# MB9BF40xN register map
File version: 1.7
Registers are 8-bit, read-write, reset 0x0 unless marked. A register's access mark holds for its fields unless they carry their own. Offsets are from the block's base; [hi:lo] are bit positions; {n}, {i} and the like mark numbered series; 'fields as' and 'values as' point back to an identical list.

## QPRC0 — Quadrature Position/Revolution Counter 0
Base 0x40026000
Same registers: QPRC1 0x40026040
0x00 QPCR 16-bit — QPRC Position Count Register
0x04 QRCR 16-bit — QPRC Revolution Count Register
0x08 QPCCR 16-bit — QPRC Position Counter Compare Register
0x0C QPRCR 16-bit — QPRC Position and Revolution Counter Compare Register
0x10 QMPR 16-bit reset 0xFFFF — QPRC Maximum Position Register
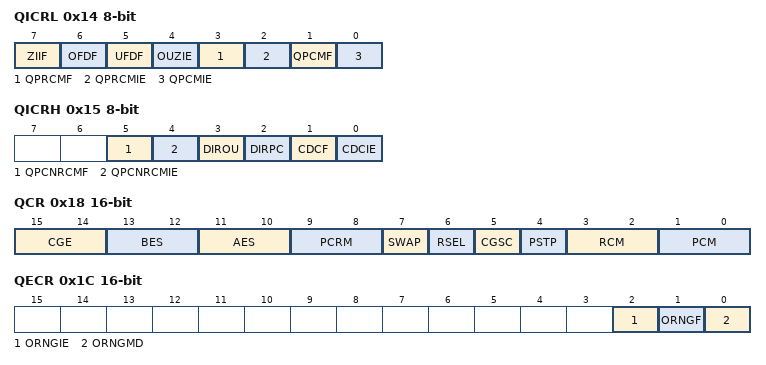
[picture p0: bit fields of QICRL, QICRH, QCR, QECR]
0x14 QICRL — Low-Order Bytes of QPRC Interrupt Control Register
  [7] ZIIF — Zero index interrupt request flag bit
  [6] OFDF — Overflow interrupt request flag bit
  [5] UFDF — Underflow interrupt request flag bit
  [4] OUZIE — "Overflow, underflow, or zero index interrupt enable bit"
  [3] QPRCMF — PC and RC match interrupt request flag bit
  [2] QPRCMIE — PC and RC match interrupt enable bit
  [1] QPCMF — PC match interrupt request flag bit
  [0] QPCMIE — PC match interrupt enable bit
0x15 QICRH — High-Order Bytes of QPRC Interrupt Control Register
  [5] QPCNRCMF — PC match and RC match interrupt request flag bit
  [4] QPCNRCMIE — PC match and RC match interrupt enable bit
  [3] DIROU ro — Last position counter flow direction bit
  [2] DIRPC ro — Last position counter direction bit
  [1] CDCF — Count inversion interrupt request flag bit
  [0] CDCIE — Count inversion interrupt enable bit
0x18 QCR 16-bit — QPRC Control Register
  [15:14] CGE — Detection edge selection bits
  [13:12] BES — BIN detection edge selection bits
  [11:10] AES — AIN detection edge selection bits
  [9:8] PCRM — Position counter reset mask bits
  [7] SWAP — Swap bit
  [6] RSEL — Register function selection bit
  [5] CGSC — Count clear or gate selection bit
  [4] PSTP — Position counter stop bit
  [3:2] RCM — Revolution counter mode bits
  [1:0] PCM — Position counter mode bits
0x1C QECR 16-bit — QPRC Extension Control Register
  [2] ORNGIE — Outrange interrupt enable bit
  [1] ORNGF — Outrange interrupt request flag bit
  [0] ORNGMD — Outrange mode selection bit

## WC — Watch Counter
Base 0x4003A000
0x00 WCRD ro — Watch Counter Read Register
  [5:0] CTR — counter value
0x01 WCRL — Watch Counter Reload Register
  [5:0] RLC — reload value
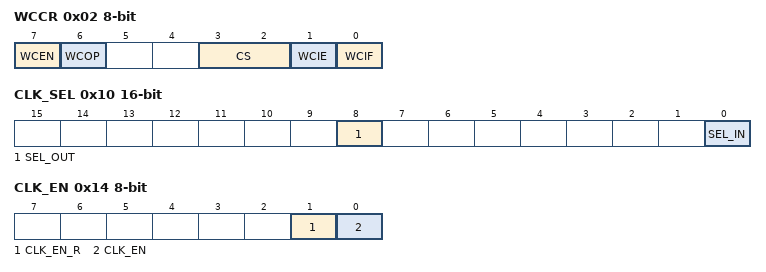
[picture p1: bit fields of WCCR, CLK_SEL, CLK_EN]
0x02 WCCR — Watch Counter Control Register
  [7] WCEN — Watch counter operation enable bit
  [6] WCOP ro — Watch counter operating state flag
  [3:2] CS — Count clock select bits
  [1] WCIE — Interrupt request enable bit
  [0] WCIF — Interrupt request flag bit
0x10 CLK_SEL 16-bit — Clock Selection Register
  [8] SEL_OUT — Output clock selection bit
  [0] SEL_IN — Input clock selection bit
0x14 CLK_EN — Division Clock Enable Register
  [1] CLK_EN_R — Division clock enable read bit
  [0] CLK_EN — Division clock enable bit

## EXTI — External Interrupt and NMI Control
Base 0x40030000
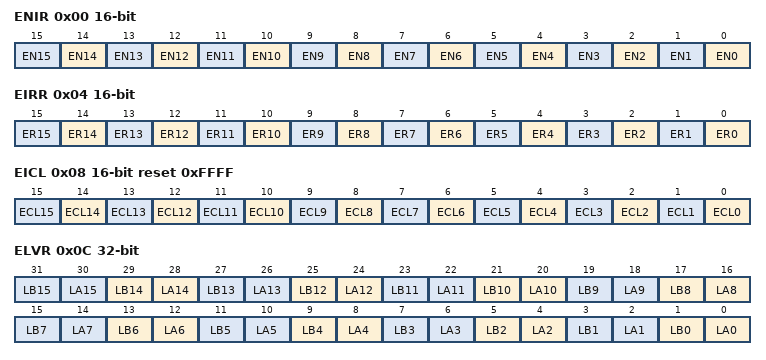
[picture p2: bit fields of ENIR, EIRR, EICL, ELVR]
0x00 ENIR 16-bit — Enable Interrupt Request Register
  [n] EN{n} (n=0..15) — Bit{n} of ENIR
0x04 EIRR 16-bit ro reset not defined — External Interrupt Request Register
  [n] ER{n} (n=0..15) — Bit{n} of EIRR
0x08 EICL 16-bit reset 0xFFFF — External Interrupt Clear Register
  [n] ECL{n} (n=0..15) — Bit{n} of EICL
0x0C ELVR 32-bit — External Interrupt Level Register
  [2n+1] LB{n} (n=0..15) — Bit{2n+1} of ELVR
  [2n] LA{n} (n=0..15) — Bit{2n} of ELVR
0x14 NMIRR ro — Non Maskable Interrupt Request Register
  [0] NR — NMI interrupt request detection bit
0x18 NMICL reset 0x1 — Non Maskable Interrupt Clear Register
  [0] NCL — NMI interrupt cause clear bit

## LVD — Low-voltage Detection
Base 0x40035000
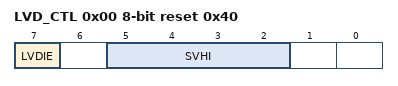
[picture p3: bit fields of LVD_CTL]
0x00 LVD_CTL reset 0x40 — Low-voltage Detection Voltage Control Register
  [7] LVDIE — Low-voltage detection interrupt enable bit
  [5:2] SVHI — Low-voltage detection interrupt voltage setting bits
0x04 LVD_STR ro — Low-voltage Detection Interrupt Register
  [7] LVDIR — Low-voltage detection interrupt bit
0x08 LVD_CLR reset 0x80 — Low-voltage Detection Interrupt Clear Register
  [7] LVDCL — Low-voltage detection interrupt clear bit
0x0C LVD_RLR 32-bit reset 0x1 — Low-voltage Detection Voltage Protection Register
  [31:0] LVDLCK — Low-voltage Detection Voltage Control Register protection bits
0x10 LVD_STR2 ro reset 0x40 — Low-voltage Detection Circuit Status Register
  [7] LVDIRDY — Low-voltage detection interrupt status flag

## CRC — CRC Registers
Base 0x40039000
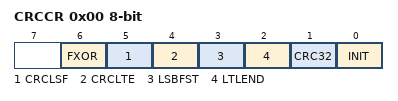
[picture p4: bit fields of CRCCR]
0x00 CRCCR — CRC Control Register
  [6] FXOR — Initialization bit
  [5] CRCLSF — Final XOR control bit
  [4] CRCLTE — CRC result bit-order setting bit
  [3] LSBFST — CRC result byte-order setting bit
  [2] LTLEND — Bit-order setting bit
  [1] CRC32 — Byte-order setting bit
  [0] INIT — CRC mode selection bit
0x04 CRCINIT 32-bit reset 0xFFFFFFFF — Initial Value Register
  [31:0] D — Initial value
0x08 CRCIN 32-bit — Input Data Register
  [31:0] D — Input data
0x0C CRCR 32-bit ro reset 0xFFFFFFFF — CRC Register
  [31:0] D — CRC Data

## EXBUS — External Bus Interface
Base 0x4003F000
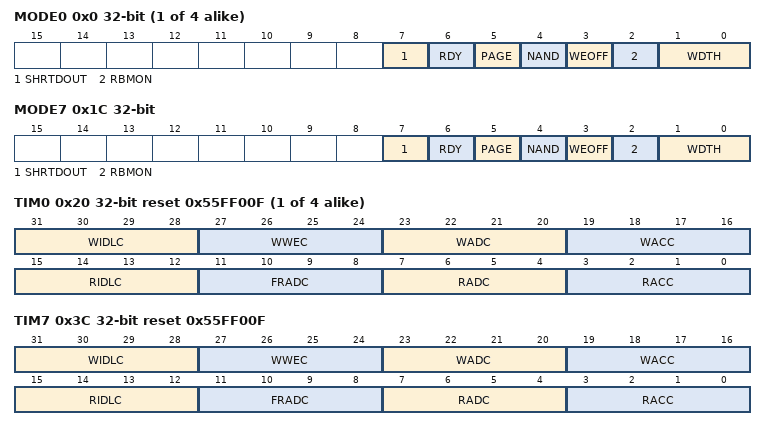
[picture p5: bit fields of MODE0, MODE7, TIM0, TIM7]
{0x0+4i} MODE{i} 32-bit (i=0..3) — Mode Register {i}
  [7] SHRTDOUT — select to which idle cycle the write data output is extended
  [6] RDY — control the external RDY function
  [5] PAGE — NOR Flash memory page access mode
  [4] NAND — NAND Flash memory mode
  [3] WEOFF — disable the write enable signal (MWEX) operation
  [2] RBMON — Read Byte Mask ON
  [1:0] WDTH — specify Data Width
0x1C MODE7 32-bit — Mode Register 7
  fields as MODE0
{0x20+4i} TIM{i} 32-bit reset 0x55FF00F (i=0..3) — Timing Register {i}
  [31:28] WIDLC — Write Idle Cycle
  [27:24] WWEC — Write Enable Cycle
  [23:20] WADC — Write Address Setup cycle
  [19:16] WACC — Write Access Cycle
  [15:12] RIDLC — Read Idle Cycle
  [11:8] FRADC — First Read Address Cycle
  [7:4] RADC — Read Address Setup cycle
  [3:0] RACC — Read Access Cycle
0x3C TIM7 32-bit reset 0x55FF00F — Timing Register 7
  fields as TIM0
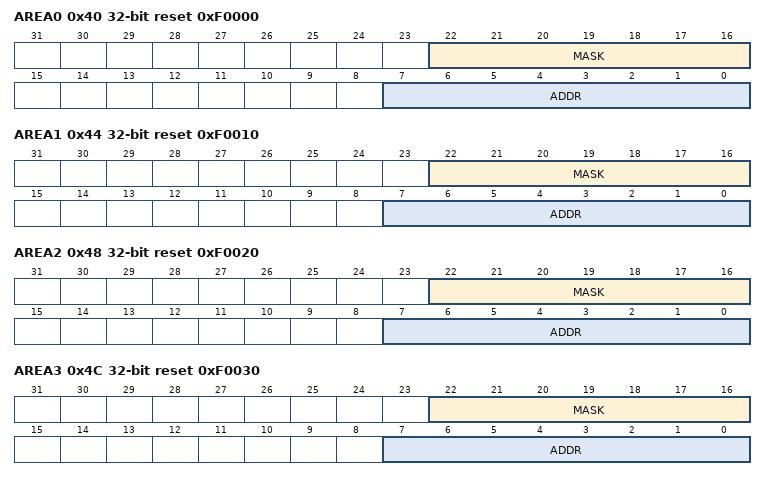
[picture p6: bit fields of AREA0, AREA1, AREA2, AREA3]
0x40 AREA0 32-bit reset 0xF0000 — Area Register 0
  [22:16] MASK — address mask
  [7:0] ADDR — Address
0x44 AREA1 32-bit reset 0xF0010 — Area Register 1
  [22:16] MASK — address mask
  [7:0] ADDR — Address
0x48 AREA2 32-bit reset 0xF0020 — Area Register 2
  [22:16] MASK — address mask
  [7:0] ADDR — Address
0x4C AREA3 32-bit reset 0xF0030 — Area Register 3
  [22:16] MASK — address mask
  [7:0] ADDR — Address
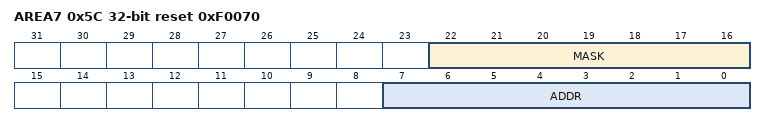
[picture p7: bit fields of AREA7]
0x5C AREA7 32-bit reset 0xF0070 — Area Register 7
  [22:16] MASK — address mask
  [7:0] ADDR — Address

## DMAC — DMAC Registers
Base 0x40060000
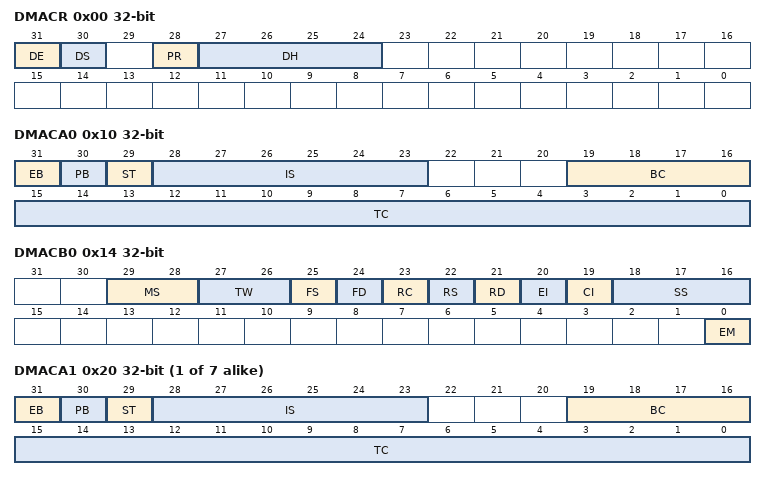
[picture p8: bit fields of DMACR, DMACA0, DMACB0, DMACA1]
0x00 DMACR 32-bit — Entire DMAC Configuration Register
  [31] DE — DMA Enable (all-channel operation enable bit)
  [30] DS — DMA Stop
  [28] PR — Priority Rotation
  [27:24] DH — DMA Halt (All-channel pause bit)
0x10 DMACA0 32-bit — Configuration A Register
  [31] EB — Enable bit (individual-channel operation enable bit)
  [30] PB — Pause bit (individual-channel pause bit)
  [29] ST — Software Trigger
  [28:23] IS — Input Select
  [19:16] BC — Block Count
  [15:0] TC — Transfer Count
0x14 DMACB0 32-bit — Configuration B Register
  [29:28] MS — Mode Select
  [27:26] TW — Transfer Width
  [25] FS — Fixed Source
  [24] FD — Fixed Destination
  [23] RC — Reload Count (BC/TC reload)
  [22] RS — Reload Source
  [21] RD — Reload Destination
  [20] EI — Error Interrupt (unsuccessful transfer completion interrupt enable)
  [19] CI — Completion Interrupt (successful transfer completion interrupt enable)
  [18:16] SS — Stop Status (stop status notification)
  [0] EM — Enable bit Mask (EB bit clear mask)
0x18 DMACSA0 32-bit — Transfer Source Address Register
0x1C DMACDA0 32-bit — Transfer Destination Address Register
{0x10+0x10*i} DMACA{i} 32-bit (i=1..7) — Configuration A Register {i}
  fields as DMACA0
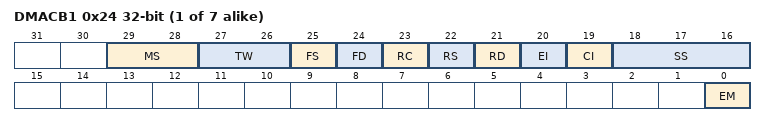
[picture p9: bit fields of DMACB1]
{0x14+0x10*i} DMACB{i} 32-bit (i=1..7) — Configuration B Register {i}
  fields as DMACB0
{0x18+0x10*i} DMACSA{i} 32-bit (i=1..7) — Transfer Source Address Register {i}
{0x1C+0x10*i} DMACDA{i} 32-bit (i=1..7) — Transfer Destination Address Register {i}

## CANPRES — CAN Prescaler Register
Base 0x40037000
0x00 CANPRE reset 0xB (reset mask 0xF) — CAN Prescaler Register

## Notices in the file
Licence Terms
FUJITSU SEMICONDUCTOR LIMITED (gLICENSORh) hereby grants and
you (gLICENSEEh) hereby accept a non transferable, non-exclusive
licence to use and copy the deliverables (gDeliverablesh) solely for
the purpose of; (i) developing LICENSEEfs development tools and
distributing such development tools to third parties; (ii) generating
derivative representations of the Deliverables to develop and debug
software for LICENSORfs targeted devices or device series identified
within the Deliverables, (together the gPurposeh) under the following
terms and conditions:
1. Ownership.
The Deliverables are the property of LICENSOR. LICENSEE acquires no
right, title or interest in the Deliverables other than the licence
rights granted herein.
2. Use.
LICENSEE shall only be permitted to use the Deliverables for the
Purpose. LICENSEE shall not reverse engineer, decompile or
disassemble the Deliverables, in whole or in part.
3. Copies.
All copies of the Deliverables must bear the same notice(s) contained
on the original copies of the Deliverables.
4. No Warranty.
THE DELIVERABLES ARE PROVIDED gAS ISh AND ANY EXPRESS, IMPLIED OR
STATUTORY WARRANTIES, INCLUDING, BUT NOT LIMITED TO, THE IMPLIED
WARRANTIES OF MERCHANTABILITY, SATISFACTORY QUALITY AND FITNESS FOR
A PARTICULAR PURPOSE ARE DISCLAIMED.
IN NO EVENT SHALL LICENSOR BE LIABLE FOR ANY DIRECT, INDIRECT,
INCIDENTAL, SPECIAL, EXEMPLARY, OR CONSEQUENTIAL DAMAGES HOWEVER CAUSED
AND ON ANY THEORY OF LIABILITY, WHETHER IN CONTRACT, STRICT LIABILITY,
OR TORT (INCLUDING NEGLIGENCE OR OTHERWISE) ARISING IN ANY WAY OUT OF
THE USE OF THE DELIVERABLES, EVEN IF ADVISED OF THE POSSIBILITY OF SUCH
DAMAGE.
LICENSEE EXPRESSLY ASSUMES ALL LIABILITIES AND RISKS, FOR USE OR
OPERATION OF THE DELIVERABLES.
5.In the event that LICENSEE receives early access to the Deliverables,
LICENSEE acknowledges and agrees that;
(a) notwithstanding the licence grants above, LICENSEE shall only be
permitted to use the Deliverables solely internally for evaluation and
providing feedback to LICENSOR;
(b) except with respect to the limited licence grants in 5(a), LICENSEE
shall be subject to all of the terms and conditions set out above; and
(c) the Deliverables are confidential information and LICENSEE shall
maintain in confidence the Deliverables and apply security measures no
less stringent than the measures that LICENSEE applies to its own like
information, but not less than a reasonable degree of care, to prevent
unauthorised disclosure and use of the Deliverables.
